# CH32L103 register map
Vendor: WCH Ltd.; File version: 1.3
Registers are 32-bit, read-write, reset 0x0 unless marked. A register's access mark holds for its fields unless they carry their own. Offsets are from the block's base; [hi:lo] are bit positions; lines under a group give offsets from that group; {n}, {i} and the like mark numbered series.

## ADC__TKEY — Analog to digital converter_TOUCHKEY detection
Base 0x40012400
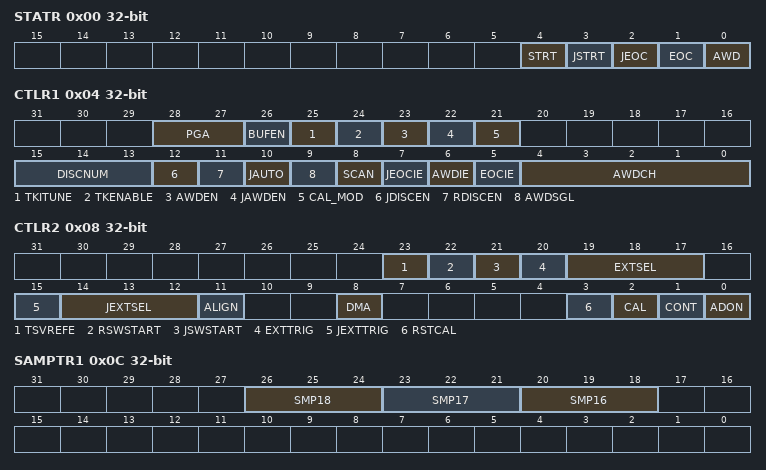
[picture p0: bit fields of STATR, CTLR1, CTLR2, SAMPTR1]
0x00 STATR — status register
  [4] STRT — Regular channel start flag
  [3] JSTRT — Injected channel start flag
  [2] JEOC — Injected channel end of conversion
  [1] EOC — Regular channel end of conversion
  [0] AWD — Analog watchdog flag
0x04 CTLR1 — control register 1
  [28:27] PGA — ADC_PGA
  [26] BUFEN — TKEY_BUF_Enable
  [25] TKITUNE — TKEY_I enable
  [24] TKENABLE — TKEY enable, including TKEY_F and TKEY_V
  [23] AWDEN — Analog watchdog enable on regular channels
  [22] JAWDEN — Analog watchdog enable on injected channels
  [21] CAL_MOD — ADC calibration mode control
  [15:13] DISCNUM — Discontinuous mode channel count
  [12] JDISCEN — Discontinuous mode on injected channels
  [11] RDISCEN — Discontinuous mode on regular channels
  [10] JAUTO — Automatic injected group conversion
  [9] AWDSGL — Enable the watchdog on a single channel in scan mode
  [8] SCAN — Scan mode enable
  [7] JEOCIE — Interrupt enable for injected channels
  [6] AWDIE — Analog watchdog interrupt enable
  [5] EOCIE — Interrupt enable for EOC
  [4:0] AWDCH — Analog watchdog channel select bits
0x08 CTLR2 — control register 2
  [23] TSVREFE — Temperature sensor and VREFINT enable
  [22] RSWSTART — Start conversion of regular channels
  [21] JSWSTART — Start conversion of injected channels
  [20] EXTTRIG — External trigger conversion mode for regular channels
  [19:17] EXTSEL — External event select for regular group
  [15] JEXTTRIG — External trigger conversion mode for injected channels
  [14:12] JEXTSEL — External event select for injected group
  [11] ALIGN — Data alignment
  [8] DMA — Direct memory access mode
  [3] RSTCAL — Reset calibration
  [2] CAL — A/D calibration
  [1] CONT — Continuous conversion
  [0] ADON — A/D converter ON / OFF
0x0C SAMPTR1 — sample time register 1
  [26:24] SMP18 — Channel 18 sample time selection
  [23:21] SMP17 — Channel 17 sample time selection
  [20:18] SMP16 — Channel 16 sample time selection
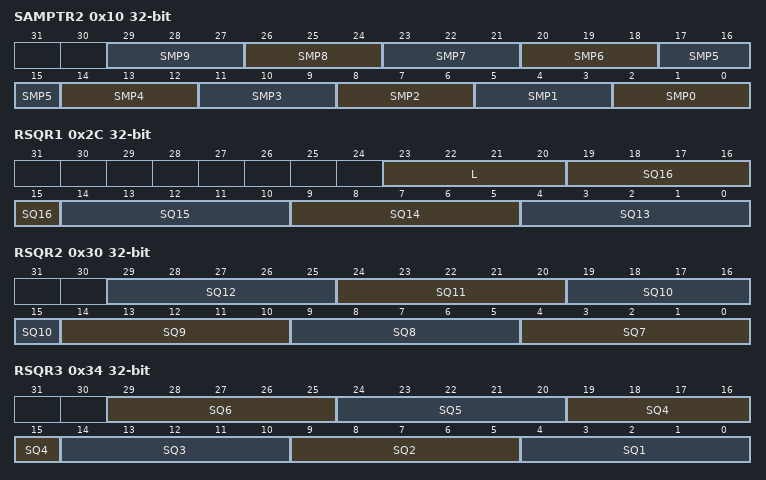
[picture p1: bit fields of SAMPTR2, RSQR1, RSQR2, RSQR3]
0x10 SAMPTR2 — sample time register 2
  [3n+2:3n] SMP{n} (n=0..9) — Channel {n} sample time selection
{0x10+4i} IOFR{i} (i=1..4) — injected channel data offset register x
  [11:0] JOFFSET{i} — Data offset for injected channel x
0x24 WDHTR reset 0xFFF — watchdog higher threshold register
  [11:0] HT — Analog watchdog higher threshold
0x28 WDLTR — watchdog lower threshold register
  [11:0] LT — Analog watchdog lower threshold
0x2C RSQR1 — regular sequence register 1
  [23:20] L — Regular channel sequence length
  [5n-61:5n-65] SQ{n} (n=13..16) — {n}th conversion in regular sequence
0x30 RSQR2 — regular sequence register 2
  [5n-31:5n-35] SQ{n} (n=7..12) — {n}th conversion in regular sequence
0x34 RSQR3 — regular sequence register 3
  [29:25] SQ6 — 6th conversion in regular sequence
  [24:20] SQ5 — 5th conversion in regular sequence
  [19:15] SQ4 — 4th conversion in regular sequence
  [14:10] SQ3 — 3rd conversion in regular sequence
  [9:5] SQ2 — 2nd conversion in regular sequence
  [4:0] SQ1 — 1st conversion in regular sequence
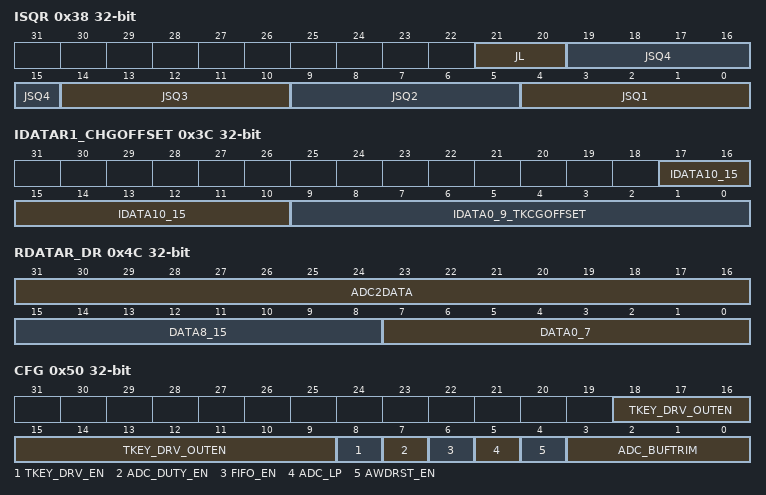
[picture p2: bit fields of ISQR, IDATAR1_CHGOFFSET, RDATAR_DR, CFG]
0x38 ISQR — injected sequence register
  [21:20] JL — Injected sequence length
  [19:15] JSQ4 — 4th conversion in injected sequence
  [14:10] JSQ3 — 3rd conversion in injected sequence
  [9:5] JSQ2 — 2nd conversion in injected sequence
  [4:0] JSQ1 — 1st conversion in injected sequence
0x3C IDATAR1_CHGOFFSET ro — injected data register 1
  [17:10] IDATA10_15 — Injected data
  [9:0] IDATA0_9_TKCGOFFSET — Injected data_Touch key charge data offset for injected channel x
{0x38+4i} IDATAR{i} ro (i=2..4) — injected data register {i}
  [15:0] JDATA — Injected data
0x4C RDATAR_DR ro — regular data register
  [31:16] ADC2DATA — converter data
  [15:8] DATA8_15 — Regular data
  [7:0] DATA0_7 — Regular data
0x4C ACT_DCG wo (alternate view of RDATAR_DR) — start and discharge time register
  [7:0] TKACT_DCG — Touch key start and discharge time register
0x50 CFG — ADC configuration register
  [18:9] TKEY_DRV_OUTEN — TOUCHKEY shielded each channel enable
  [8] TKEY_DRV_EN — TOUCHKEY shielded enable
  [7] ADC_DUTY_EN — ADC clock duty control
  [6] FIFO_EN — ADC FIFO enable
  [5] ADC_LP — ADC low-power mode control
  [4] AWDRST_EN — AWD reset enable
  [3:0] ADC_BUFTRIM — ADC buffer misalignment control
